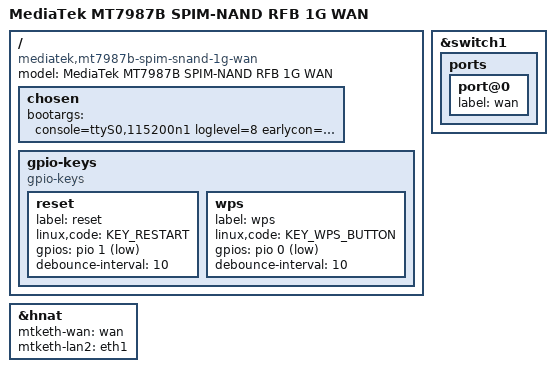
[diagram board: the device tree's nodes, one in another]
/* SPDX-License-Identifier: (GPL-2.0 OR MIT) */

/dts-v1/;
#include "mt7987b.dtsi"
#include "mt7987-netsys-gmac12.dtsi"
#include "mt7987-spim-nand.dtsi"
#include <dt-bindings/input/input.h>

/ {
	model = "MediaTek MT7987B SPIM-NAND RFB 1G WAN";
	compatible = "mediatek,mt7987b-spim-snand-1g-wan",
		     "mediatek,mt7987b", "mediatek,mt7987";

	chosen {
		bootargs = "console=ttyS0,115200n1 loglevel=8  \
			    earlycon=uart8250,mmio32,0x11000000 \
			    pci=pcie_bus_perf";
	};

	gpio-keys {
		compatible = "gpio-keys";

		reset {
			label = "reset";
			linux,code = <KEY_RESTART>;
			gpios = <&pio 1 GPIO_ACTIVE_LOW>;
			debounce-interval = <10>;
		};

		wps {
			label = "wps";
			linux,code = <KEY_WPS_BUTTON>;
			gpios = <&pio 0 GPIO_ACTIVE_LOW>;
			debounce-interval = <10>;
		};
	};
};

&hnat {
	mtketh-wan = "wan";
	mtketh-lan2 = "eth1";
};

&switch1 {
	ports {
		port@0 {
			label = "wan";
		};
	};
};
